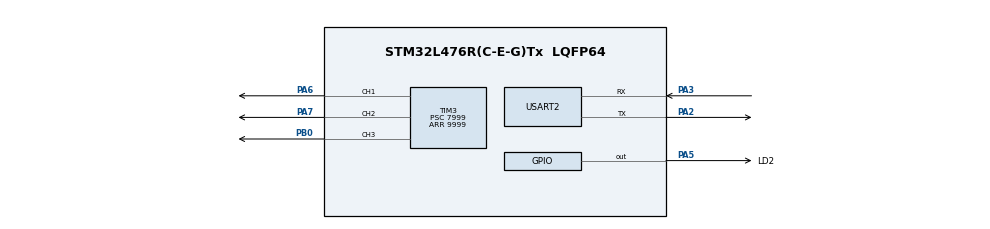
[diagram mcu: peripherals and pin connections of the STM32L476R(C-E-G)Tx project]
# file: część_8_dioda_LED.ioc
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Mcu.Family=STM32L4
Mcu.Name=STM32L476R(C-E-G)Tx
Mcu.Package=LQFP64
NVIC.PriorityGroup=NVIC_PRIORITYGROUP_4
PA13\ (JTMS-SWDIO).Mode=Serial_Wire
PA13\ (JTMS-SWDIO).Signal=SYS_JTMS-SWDIO
PA14\ (JTCK-SWCLK).Mode=Serial_Wire
PA14\ (JTCK-SWCLK).Signal=SYS_JTCK-SWCLK
PA2.Mode=Asynchronous
PA2.Signal=USART2_TX
PA3.Mode=Asynchronous
PA3.Signal=USART2_RX
PA5.GPIO_Label=LD2
PA5.Signal=GPIO_Output
PA6.Signal=S_TIM3_CH1
PA7.Signal=S_TIM3_CH2
PB0.Signal=S_TIM3_CH3
PC14-OSC32_IN\ (PC14).Mode=LSE-External-Oscillator
PC14-OSC32_IN\ (PC14).Signal=RCC_OSC32_IN
PC15-OSC32_OUT\ (PC15).Mode=LSE-External-Oscillator
PC15-OSC32_OUT\ (PC15).Signal=RCC_OSC32_OUT
ProjectManager.HeapSize=0x200
ProjectManager.StackSize=0x400
ProjectManager.TargetToolchain=STM32CubeIDE
RCC.HSE_VALUE=8000000
RCC.HSI_VALUE=16000000
RCC.MSI_VALUE=4000000
RCC.VCOOutputFreq_Value=32000000
SH.S_TIM3_CH1.0=TIM3_CH1,PWM Generation1 CH1
SH.S_TIM3_CH2.0=TIM3_CH2,PWM Generation2 CH2
SH.S_TIM3_CH3.0=TIM3_CH3,PWM Generation3 CH3
TIM3.Channel-PWM\ Generation1\ CH1=TIM_CHANNEL_1
TIM3.Channel-PWM\ Generation2\ CH2=TIM_CHANNEL_2
TIM3.Channel-PWM\ Generation3\ CH3=TIM_CHANNEL_3
TIM3.OCPolarity_1=TIM_OCPOLARITY_LOW
TIM3.OCPolarity_2=TIM_OCPOLARITY_LOW
TIM3.OCPolarity_3=TIM_OCPOLARITY_LOW
TIM3.Period=9999
TIM3.Prescaler=7999
TIM3.Pulse-PWM\ Generation1\ CH1=50
TIM3.Pulse-PWM\ Generation2\ CH2=400
TIM3.Pulse-PWM\ Generation3\ CH3=2000
USART2.VirtualMode-Asynchronous=VM_ASYNC
VP_TIM3_VS_ClockSourceINT.Mode=Internal
board=custom

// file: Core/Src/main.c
/* USER CODE BEGIN Header */
/**
  ******************************************************************************
  * @file           : main.c
  * @brief          : Main program body
  ******************************************************************************
  * @attention
  *
  * Copyright (c) 2026 STMicroelectronics.
  * All rights reserved.
  *
  * This software is licensed under terms that can be found in the LICENSE file
  * in the root directory of this software component.
  * If no LICENSE file comes with this software, it is provided AS-IS.
  *
  ******************************************************************************
  */
/* USER CODE END Header */
#include "main.h"

/* USER CODE BEGIN Includes */
#include "math.h"
/* USER CODE END Includes */

TIM_HandleTypeDef htim3;

UART_HandleTypeDef huart2;

void SystemClock_Config(void);
static void MX_GPIO_Init(void);
static void MX_TIM3_Init(void);
static void MX_USART2_UART_Init(void);

/* USER CODE BEGIN 0 */
float calc_pwm(float val)
{
    const float k = 0.13f;
    const float x0 = 70.0f;
    return 10000.0f / (1.0f + exp(-k * (val - x0)));
}
/* USER CODE END 0 */

int main(void)
{

  /* MCU Configuration--------------------------------------------------------*/

  /* Reset of all peripherals, Initializes the Flash interface and the Systick. */
  HAL_Init();

  /* Configure the system clock */
  SystemClock_Config();

  /* Initialize all configured peripherals */
  MX_GPIO_Init();
  MX_TIM3_Init();
  MX_USART2_UART_Init();

  /* Infinite loop */
  /* USER CODE BEGIN WHILE */
  int counter;
  while (1)
  {
    /* USER CODE END WHILE */
	  float r = 50 * (1.0f + sin(counter / 100.0f));
	  float g = 50 * (1.0f + sin(1.5f * counter / 100.0f));
	  float b = 50 * (1.0f + sin(2.0f * counter / 100.0f));
	  __HAL_TIM_SET_COMPARE(&htim3, TIM_CHANNEL_1, calc_pwm(b));
	  __HAL_TIM_SET_COMPARE(&htim3, TIM_CHANNEL_2, calc_pwm(g));
	  __HAL_TIM_SET_COMPARE(&htim3, TIM_CHANNEL_3, calc_pwm(r));

	  HAL_Delay(10);
	  counter++;
  }
}

void SystemClock_Config(void)
{
  RCC_OscInitTypeDef RCC_OscInitStruct = {0};
  RCC_ClkInitTypeDef RCC_ClkInitStruct = {0};

  /** Configure the main internal regulator output voltage
  */
  if (HAL_PWREx_ControlVoltageScaling(PWR_REGULATOR_VOLTAGE_SCALE1) != HAL_OK)
  {
    Error_Handler();
  }

  /** Configure LSE Drive Capability
  */
  HAL_PWR_EnableBkUpAccess();
  __HAL_RCC_LSEDRIVE_CONFIG(RCC_LSEDRIVE_LOW);

  /** Initializes the RCC Oscillators according to the specified parameters
  * in the RCC_OscInitTypeDef structure.
  */
  RCC_OscInitStruct.OscillatorType = RCC_OSCILLATORTYPE_LSE|RCC_OSCILLATORTYPE_MSI;
  RCC_OscInitStruct.LSEState = RCC_LSE_ON;
  RCC_OscInitStruct.MSIState = RCC_MSI_ON;
  RCC_OscInitStruct.MSICalibrationValue = 0;
  RCC_OscInitStruct.MSIClockRange = RCC_MSIRANGE_6;
  RCC_OscInitStruct.PLL.PLLState = RCC_PLL_NONE;
  if (HAL_RCC_OscConfig(&RCC_OscInitStruct) != HAL_OK)
  {
    Error_Handler();
  }

  /** Initializes the CPU, AHB and APB buses clocks
  */
  RCC_ClkInitStruct.ClockType = RCC_CLOCKTYPE_HCLK|RCC_CLOCKTYPE_SYSCLK
                              |RCC_CLOCKTYPE_PCLK1|RCC_CLOCKTYPE_PCLK2;
  RCC_ClkInitStruct.SYSCLKSource = RCC_SYSCLKSOURCE_MSI;
  RCC_ClkInitStruct.AHBCLKDivider = RCC_SYSCLK_DIV1;
  RCC_ClkInitStruct.APB1CLKDivider = RCC_HCLK_DIV1;
  RCC_ClkInitStruct.APB2CLKDivider = RCC_HCLK_DIV1;

  if (HAL_RCC_ClockConfig(&RCC_ClkInitStruct, FLASH_LATENCY_0) != HAL_OK)
  {
    Error_Handler();
  }

  /** Enable MSI Auto calibration
  */
  HAL_RCCEx_EnableMSIPLLMode();
}

static void MX_TIM3_Init(void)
{

  TIM_ClockConfigTypeDef sClockSourceConfig = {0};
  TIM_MasterConfigTypeDef sMasterConfig = {0};
  TIM_OC_InitTypeDef sConfigOC = {0};

  htim3.Instance = TIM3;
  htim3.Init.Prescaler = 7999;
  htim3.Init.CounterMode = TIM_COUNTERMODE_UP;
  htim3.Init.Period = 9999;
  htim3.Init.ClockDivision = TIM_CLOCKDIVISION_DIV1;
  htim3.Init.AutoReloadPreload = TIM_AUTORELOAD_PRELOAD_DISABLE;
  if (HAL_TIM_Base_Init(&htim3) != HAL_OK)
  {
    Error_Handler();
  }
  sClockSourceConfig.ClockSource = TIM_CLOCKSOURCE_INTERNAL;
  if (HAL_TIM_ConfigClockSource(&htim3, &sClockSourceConfig) != HAL_OK)
  {
    Error_Handler();
  }
  if (HAL_TIM_PWM_Init(&htim3) != HAL_OK)
  {
    Error_Handler();
  }
  sMasterConfig.MasterOutputTrigger = TIM_TRGO_RESET;
  sMasterConfig.MasterSlaveMode = TIM_MASTERSLAVEMODE_DISABLE;
  if (HAL_TIMEx_MasterConfigSynchronization(&htim3, &sMasterConfig) != HAL_OK)
  {
    Error_Handler();
  }
  sConfigOC.OCMode = TIM_OCMODE_PWM1;
  sConfigOC.Pulse = 50;
  sConfigOC.OCPolarity = TIM_OCPOLARITY_LOW;
  sConfigOC.OCFastMode = TIM_OCFAST_DISABLE;
  if (HAL_TIM_PWM_ConfigChannel(&htim3, &sConfigOC, TIM_CHANNEL_1) != HAL_OK)
  {
    Error_Handler();
  }
  sConfigOC.Pulse = 400;
  if (HAL_TIM_PWM_ConfigChannel(&htim3, &sConfigOC, TIM_CHANNEL_2) != HAL_OK)
  {
    Error_Handler();
  }
  sConfigOC.Pulse = 2000;
  if (HAL_TIM_PWM_ConfigChannel(&htim3, &sConfigOC, TIM_CHANNEL_3) != HAL_OK)
  {
    Error_Handler();
  }
  HAL_TIM_MspPostInit(&htim3);

}

static void MX_USART2_UART_Init(void)
{

  huart2.Instance = USART2;
  huart2.Init.BaudRate = 115200;
  huart2.Init.WordLength = UART_WORDLENGTH_8B;
  huart2.Init.StopBits = UART_STOPBITS_1;
  huart2.Init.Parity = UART_PARITY_NONE;
  huart2.Init.Mode = UART_MODE_TX_RX;
  huart2.Init.HwFlowCtl = UART_HWCONTROL_NONE;
  huart2.Init.OverSampling = UART_OVERSAMPLING_16;
  huart2.Init.OneBitSampling = UART_ONE_BIT_SAMPLE_DISABLE;
  huart2.AdvancedInit.AdvFeatureInit = UART_ADVFEATURE_NO_INIT;
  if (HAL_UART_Init(&huart2) != HAL_OK)
  {
    Error_Handler();
  }

}

static void MX_GPIO_Init(void)
{
  GPIO_InitTypeDef GPIO_InitStruct = {0};

  /* GPIO Ports Clock Enable */
  __HAL_RCC_GPIOC_CLK_ENABLE();
  __HAL_RCC_GPIOA_CLK_ENABLE();
  __HAL_RCC_GPIOB_CLK_ENABLE();

  /*Configure GPIO pin Output Level */
  HAL_GPIO_WritePin(LD2_GPIO_Port, LD2_Pin, GPIO_PIN_RESET);

  /*Configure GPIO pin : LD2_Pin */
  GPIO_InitStruct.Pin = LD2_Pin;
  GPIO_InitStruct.Mode = GPIO_MODE_OUTPUT_PP;
  GPIO_InitStruct.Pull = GPIO_NOPULL;
  GPIO_InitStruct.Speed = GPIO_SPEED_FREQ_LOW;
  HAL_GPIO_Init(LD2_GPIO_Port, &GPIO_InitStruct);

}

void Error_Handler(void)
{
  __disable_irq();
  while (1)
  {
  }
}
